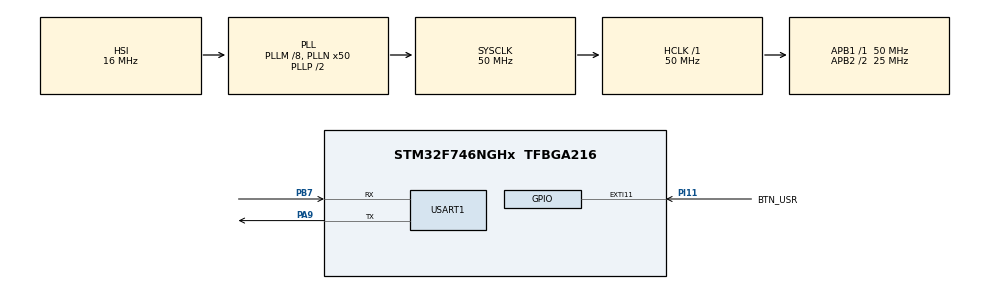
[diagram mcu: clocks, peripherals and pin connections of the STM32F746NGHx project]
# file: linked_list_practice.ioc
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FREERTOS.Mutexes01=linkedL,Dynamic,NULL
FREERTOS.Tasks01=defaultTask,0,128,StartDefaultTask,Default,NULL,Dynamic,NULL,NULL;LinkedLPush,0,256,StartLinkedLPush,Default,NULL,Dynamic,NULL,NULL;PushFront,0,256,StartPushFront,Default,NULL,Dynamic,NULL,NULL;TestTask,0,256,StartTestTask,Default,NULL,Dynamic,NULL,NULL
Mcu.Family=STM32F7
Mcu.Name=STM32F746NGHx
Mcu.Package=TFBGA216
NVIC.EXTI15_10_IRQn=true\:5\:0\:false\:false\:true\:true\:true\:true
NVIC.PriorityGroup=NVIC_PRIORITYGROUP_4
NVIC.TIM5_IRQn=true\:5\:0\:false\:false\:true\:true\:true\:true
NVIC.TIM8_TRG_COM_TIM14_IRQn=true\:0\:0\:false\:false\:true\:false\:false\:true
NVIC.TimeBase=TIM8_TRG_COM_TIM14_IRQn
NVIC.TimeBaseIP=TIM14
NVIC.USART1_IRQn=true\:5\:0\:false\:false\:true\:true\:true\:true
PA13.Mode=Serial_Wire
PA13.Signal=SYS_JTMS-SWDIO
PA14.Mode=Serial_Wire
PA14.Signal=SYS_JTCK-SWCLK
PA9.Mode=Asynchronous
PA9.Signal=USART1_TX
PB7.Mode=Asynchronous
PB7.Signal=USART1_RX
PC14/OSC32_IN.Mode=LSE-External-Oscillator
PC14/OSC32_IN.Signal=RCC_OSC32_IN
PC15/OSC32_OUT.Mode=LSE-External-Oscillator
PC15/OSC32_OUT.Signal=RCC_OSC32_OUT
PH0/OSC_IN.Mode=HSE-External-Clock-Source
PH0/OSC_IN.Signal=RCC_OSC_IN
PH1/OSC_OUT.Mode=HSE-External-Clock-Source
PH1/OSC_OUT.Signal=RCC_OSC_OUT
PI11.GPIO_Label=BTN_USR
PI11.Signal=GPXTI11
ProjectManager.HeapSize=0x200
ProjectManager.StackSize=0x400
ProjectManager.TargetToolchain=STM32CubeIDE
RCC.AHBFreq_Value=50000000
RCC.APB1Freq_Value=50000000
RCC.APB1TimFreq_Value=50000000
RCC.APB2CLKDivider=RCC_HCLK_DIV2
RCC.APB2Freq_Value=25000000
RCC.APB2TimFreq_Value=50000000
RCC.CortexFreq_Value=50000000
RCC.HCLKFreq_Value=50000000
RCC.HSE_VALUE=25000000
RCC.HSI_VALUE=16000000
RCC.PLLM=8
RCC.PLLN=50
RCC.PLLQ=3
RCC.PLLSourceVirtual=RCC_PLLSOURCE_HSI
RCC.SYSCLKFreq_VALUE=50000000
RCC.SYSCLKSource=RCC_SYSCLKSOURCE_PLLCLK
RCC.USBFreq_Value=33333333.333333332
RCC.VCOOutputFreq_Value=100000000
TIM5.Period=30000
TIM5.Prescaler=5000-1
USART1.VirtualMode-Asynchronous=VM_ASYNC
VP_FREERTOS_VS_CMSIS_V1.Mode=CMSIS_V1
VP_RNG_VS_RNG.Mode=RNG_Activate
VP_SYS_VS_tim14.Mode=TIM14
VP_TIM5_VS_ClockSourceINT.Mode=Internal
board=STM32F746G-DISCO

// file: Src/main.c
/* USER CODE BEGIN Header */
/**
  ******************************************************************************
  * @file           : main.c
  * @brief          : Main program body
  ******************************************************************************
  * @attention
  *
  * <h2><center>&copy; Copyright (c) 2019 STMicroelectronics.
  * All rights reserved.</center></h2>
  *
  * This software component is licensed by ST under BSD 3-Clause license,
  * the "License"; You may not use this file except in compliance with the
  * License. You may obtain a copy of the License at:
  *                        opensource.org/licenses/BSD-3-Clause
  *
  ******************************************************************************
  */
/* USER CODE END Header */

#include "main.h"
#include "cmsis_os.h"

/* USER CODE BEGIN Includes */
#include "linked_list.h"
#include <string.h>
#include <stdio.h>
/* USER CODE END Includes */

RNG_HandleTypeDef hrng;

TIM_HandleTypeDef htim5;

UART_HandleTypeDef huart1;

osThreadId defaultTaskHandle;
osThreadId LinkedLPushHandle;
osThreadId PushFrontHandle;
osThreadId TestTaskHandle;
osMutexId linkedLHandle;
/* USER CODE BEGIN PV */
int sys_init_tim = 0;
node_t* linked_list;
/* USER CODE END PV */

void SystemClock_Config(void);
static void MX_GPIO_Init(void);
static void MX_RNG_Init(void);
static void MX_TIM5_Init(void);
static void MX_USART1_UART_Init(void);
void StartDefaultTask(void const * argument);
void StartLinkedLPush(void const * argument);
void StartPushFront(void const * argument);
void StartTestTask(void const * argument);

/* USER CODE BEGIN PFP */
//void print_linked_list();
void test_uart();
/* USER CODE END PFP */

/* USER CODE BEGIN 0 */
void print_linked_list()
{
	int element_counter = 0;
	for(node_t* p = linked_list; p != NULL; p = p->next){
	  char tmp[128];
	  sprintf(tmp, "List element at %d.: %d\n", (element_counter + 1), p->data);
	  HAL_UART_Transmit(&huart1, (uint8_t*)tmp, strlen(tmp), 50);
	  element_counter++;
	}
}

void test_uart()
{
	char tmp[32];
	sprintf(tmp, "Fuck everything\r\n");
	HAL_UART_Transmit(&huart1, (uint8_t*)tmp, strlen(tmp), 50);
}
/* USER CODE END 0 */

int main(void)
{

  /* MCU Configuration--------------------------------------------------------*/

  /* Reset of all peripherals, Initializes the Flash interface and the Systick. */
  HAL_Init();

  /* Configure the system clock */
  SystemClock_Config();

  /* USER CODE BEGIN SysInit */
  linked_list_create(&linked_list);
  /* USER CODE END SysInit */

  /* Initialize all configured peripherals */
  MX_GPIO_Init();
  MX_RNG_Init();
  MX_TIM5_Init();
  MX_USART1_UART_Init();
  /* USER CODE BEGIN 2 */
  HAL_TIM_Base_Start_IT(&htim5);
  /* USER CODE END 2 */

  /* Create the mutex(es) */
  /* definition and creation of linkedL */
  osMutexDef(linkedL);
  linkedLHandle = osMutexCreate(osMutex(linkedL));

  /* Create the thread(s) */
  /* definition and creation of defaultTask */
  osThreadDef(defaultTask, StartDefaultTask, osPriorityNormal, 0, 128);
  defaultTaskHandle = osThreadCreate(osThread(defaultTask), NULL);

  /* definition and creation of LinkedLPush */
  osThreadDef(LinkedLPush, StartLinkedLPush, osPriorityNormal, 0, 256);
  LinkedLPushHandle = osThreadCreate(osThread(LinkedLPush), NULL);

  /* definition and creation of PushFront */
  osThreadDef(PushFront, StartPushFront, osPriorityNormal, 0, 256);
  PushFrontHandle = osThreadCreate(osThread(PushFront), NULL);

  /* definition and creation of TestTask */
  osThreadDef(TestTask, StartTestTask, osPriorityNormal, 0, 256);
  TestTaskHandle = osThreadCreate(osThread(TestTask), NULL);

  /* Start scheduler */
  osKernelStart();

  /* We should never get here as control is now taken by the scheduler */

  /* Infinite loop */
  while (1)
  {

  }
}

void SystemClock_Config(void)
{
  RCC_OscInitTypeDef RCC_OscInitStruct = {0};
  RCC_ClkInitTypeDef RCC_ClkInitStruct = {0};
  RCC_PeriphCLKInitTypeDef PeriphClkInitStruct = {0};

  /** Configure LSE Drive Capability
  */
  HAL_PWR_EnableBkUpAccess();
  /** Configure the main internal regulator output voltage
  */
  __HAL_RCC_PWR_CLK_ENABLE();
  __HAL_PWR_VOLTAGESCALING_CONFIG(PWR_REGULATOR_VOLTAGE_SCALE3);
  /** Initializes the CPU, AHB and APB busses clocks
  */
  RCC_OscInitStruct.OscillatorType = RCC_OSCILLATORTYPE_HSI;
  RCC_OscInitStruct.HSIState = RCC_HSI_ON;
  RCC_OscInitStruct.HSICalibrationValue = RCC_HSICALIBRATION_DEFAULT;
  RCC_OscInitStruct.PLL.PLLState = RCC_PLL_ON;
  RCC_OscInitStruct.PLL.PLLSource = RCC_PLLSOURCE_HSI;
  RCC_OscInitStruct.PLL.PLLM = 8;
  RCC_OscInitStruct.PLL.PLLN = 50;
  RCC_OscInitStruct.PLL.PLLP = RCC_PLLP_DIV2;
  RCC_OscInitStruct.PLL.PLLQ = 3;
  if (HAL_RCC_OscConfig(&RCC_OscInitStruct) != HAL_OK)
  {
    Error_Handler();
  }
  /** Activate the Over-Drive mode
  */
  if (HAL_PWREx_EnableOverDrive() != HAL_OK)
  {
    Error_Handler();
  }
  /** Initializes the CPU, AHB and APB busses clocks
  */
  RCC_ClkInitStruct.ClockType = RCC_CLOCKTYPE_HCLK|RCC_CLOCKTYPE_SYSCLK
                              |RCC_CLOCKTYPE_PCLK1|RCC_CLOCKTYPE_PCLK2;
  RCC_ClkInitStruct.SYSCLKSource = RCC_SYSCLKSOURCE_PLLCLK;
  RCC_ClkInitStruct.AHBCLKDivider = RCC_SYSCLK_DIV1;
  RCC_ClkInitStruct.APB1CLKDivider = RCC_HCLK_DIV1;
  RCC_ClkInitStruct.APB2CLKDivider = RCC_HCLK_DIV2;

  if (HAL_RCC_ClockConfig(&RCC_ClkInitStruct, FLASH_LATENCY_1) != HAL_OK)
  {
    Error_Handler();
  }
  PeriphClkInitStruct.PeriphClockSelection = RCC_PERIPHCLK_USART1|RCC_PERIPHCLK_CLK48;
  PeriphClkInitStruct.Usart1ClockSelection = RCC_USART1CLKSOURCE_PCLK2;
  PeriphClkInitStruct.Clk48ClockSelection = RCC_CLK48SOURCE_PLL;
  if (HAL_RCCEx_PeriphCLKConfig(&PeriphClkInitStruct) != HAL_OK)
  {
    Error_Handler();
  }
}

static void MX_RNG_Init(void)
{

  hrng.Instance = RNG;
  if (HAL_RNG_Init(&hrng) != HAL_OK)
  {
    Error_Handler();
  }

}

static void MX_TIM5_Init(void)
{

  TIM_ClockConfigTypeDef sClockSourceConfig = {0};
  TIM_MasterConfigTypeDef sMasterConfig = {0};

  htim5.Instance = TIM5;
  htim5.Init.Prescaler = 5000-1;
  htim5.Init.CounterMode = TIM_COUNTERMODE_UP;
  htim5.Init.Period = 30000;
  htim5.Init.ClockDivision = TIM_CLOCKDIVISION_DIV1;
  htim5.Init.AutoReloadPreload = TIM_AUTORELOAD_PRELOAD_DISABLE;
  if (HAL_TIM_Base_Init(&htim5) != HAL_OK)
  {
    Error_Handler();
  }
  sClockSourceConfig.ClockSource = TIM_CLOCKSOURCE_INTERNAL;
  if (HAL_TIM_ConfigClockSource(&htim5, &sClockSourceConfig) != HAL_OK)
  {
    Error_Handler();
  }
  sMasterConfig.MasterOutputTrigger = TIM_TRGO_RESET;
  sMasterConfig.MasterSlaveMode = TIM_MASTERSLAVEMODE_DISABLE;
  if (HAL_TIMEx_MasterConfigSynchronization(&htim5, &sMasterConfig) != HAL_OK)
  {
    Error_Handler();
  }

}

static void MX_USART1_UART_Init(void)
{

  huart1.Instance = USART1;
  huart1.Init.BaudRate = 115200;
  huart1.Init.WordLength = UART_WORDLENGTH_8B;
  huart1.Init.StopBits = UART_STOPBITS_1;
  huart1.Init.Parity = UART_PARITY_NONE;
  huart1.Init.Mode = UART_MODE_TX_RX;
  huart1.Init.HwFlowCtl = UART_HWCONTROL_NONE;
  huart1.Init.OverSampling = UART_OVERSAMPLING_16;
  huart1.Init.OneBitSampling = UART_ONE_BIT_SAMPLE_DISABLE;
  huart1.AdvancedInit.AdvFeatureInit = UART_ADVFEATURE_NO_INIT;
  if (HAL_UART_Init(&huart1) != HAL_OK)
  {
    Error_Handler();
  }

}

static void MX_GPIO_Init(void)
{
  GPIO_InitTypeDef GPIO_InitStruct = {0};

  /* GPIO Ports Clock Enable */
  __HAL_RCC_GPIOA_CLK_ENABLE();
  __HAL_RCC_GPIOB_CLK_ENABLE();
  __HAL_RCC_GPIOC_CLK_ENABLE();
  __HAL_RCC_GPIOI_CLK_ENABLE();
  __HAL_RCC_GPIOH_CLK_ENABLE();

  /*Configure GPIO pin : BTN_USR_Pin */
  GPIO_InitStruct.Pin = BTN_USR_Pin;
  GPIO_InitStruct.Mode = GPIO_MODE_IT_RISING;
  GPIO_InitStruct.Pull = GPIO_NOPULL;
  HAL_GPIO_Init(BTN_USR_GPIO_Port, &GPIO_InitStruct);

  /* EXTI interrupt init*/
  HAL_NVIC_SetPriority(EXTI15_10_IRQn, 5, 0);
  HAL_NVIC_EnableIRQ(EXTI15_10_IRQn);

}

/* USER CODE BEGIN 4 */
void HAL_GPIO_EXTI_Callback(uint16_t GPIO_Pin)
{
	if(GPIO_Pin == BTN_USR_Pin){
		osSignalSet(TestTaskHandle, 5);
	}
}
/* USER CODE END 4 */

void StartDefaultTask(void const * argument)
{

  for(;;)
  {
    osDelay(1);
  }
}

void StartLinkedLPush(void const * argument)
{
  /* USER CODE BEGIN StartLinkedLPush */
  /* Infinite loop */
  for(;;)
  {
	  osSignalWait(1, osWaitForever);
	  int random_intiger = HAL_RNG_GetRandomNumber(&hrng) % 100 + 1;
	  osMutexWait(linkedLHandle, osWaitForever);
	  linked_list_push_back(&linked_list, random_intiger);
	  print_linked_list();
	  osMutexRelease(linkedLHandle);

    osDelay(1);
  }
  /* USER CODE END StartLinkedLPush */
}

void StartPushFront(void const * argument)
{
  /* USER CODE BEGIN StartPushFront */
  /* Infinite loop */
  for(;;)
  {/*
	  osMutexWait(linkedLHandle, osWaitForever);
	  linked_list_push_front(&linked_list, 69);
	  osMutexRelease(linkedLHandle);
*/
    osDelay(1);
  }
  /* USER CODE END StartPushFront */
}

void StartTestTask(void const * argument)
{
  /* USER CODE BEGIN StartTestTask */
  /* Infinite loop */
  for(;;)
  {
	  osSignalWait(5, osWaitForever);
	  osMutexWait(linkedLHandle, osWaitForever);
	  linked_list_pop_back(&linked_list);
	  osMutexRelease(linkedLHandle);

    osDelay(1);
  }
  /* USER CODE END StartTestTask */
}

void HAL_TIM_PeriodElapsedCallback(TIM_HandleTypeDef *htim)
{
  /* USER CODE BEGIN Callback 0 */
  if(htim->Instance == TIM5){
	  if(!sys_init_tim){
		  sys_init_tim = 1;
		  return;
	  }

	  osSignalSet(LinkedLPushHandle, 1);
  }
  /* USER CODE END Callback 0 */
  if (htim->Instance == TIM14) {
    HAL_IncTick();
  }
}

void Error_Handler(void)
{
}

/************************ (C) COPYRIGHT STMicroelectronics *****END OF FILE****/
